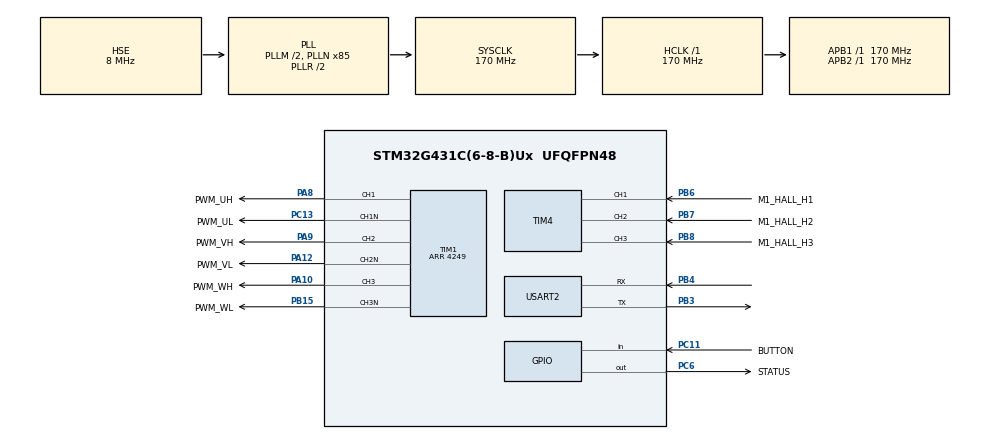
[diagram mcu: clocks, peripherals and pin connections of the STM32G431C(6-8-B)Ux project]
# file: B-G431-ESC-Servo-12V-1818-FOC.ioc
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Dma.Request0=USART2_RX
Dma.Request1=USART2_TX
Dma.USART2_RX.0.Direction=DMA_PERIPH_TO_MEMORY
Dma.USART2_RX.0.EventEnable=DISABLE
Dma.USART2_RX.0.Instance=DMA1_Channel1
Dma.USART2_RX.0.MemDataAlignment=DMA_MDATAALIGN_BYTE
Dma.USART2_RX.0.MemInc=DMA_MINC_ENABLE
Dma.USART2_RX.0.Mode=DMA_CIRCULAR
Dma.USART2_RX.0.PeriphDataAlignment=DMA_PDATAALIGN_BYTE
Dma.USART2_RX.0.PeriphInc=DMA_PINC_DISABLE
Dma.USART2_RX.0.Polarity=HAL_DMAMUX_REQ_GEN_RISING
Dma.USART2_RX.0.Priority=DMA_PRIORITY_LOW
Dma.USART2_RX.0.RequestNumber=1
Dma.USART2_RX.0.SignalID=NONE
Dma.USART2_RX.0.SyncEnable=DISABLE
Dma.USART2_RX.0.SyncPolarity=HAL_DMAMUX_SYNC_NO_EVENT
Dma.USART2_RX.0.SyncRequestNumber=1
Dma.USART2_RX.0.SyncSignalID=NONE
Dma.USART2_TX.1.Direction=DMA_MEMORY_TO_PERIPH
Dma.USART2_TX.1.EventEnable=DISABLE
Dma.USART2_TX.1.Instance=DMA1_Channel2
Dma.USART2_TX.1.MemDataAlignment=DMA_MDATAALIGN_BYTE
Dma.USART2_TX.1.MemInc=DMA_MINC_ENABLE
Dma.USART2_TX.1.Mode=DMA_NORMAL
Dma.USART2_TX.1.PeriphDataAlignment=DMA_PDATAALIGN_BYTE
Dma.USART2_TX.1.PeriphInc=DMA_PINC_DISABLE
Dma.USART2_TX.1.Polarity=HAL_DMAMUX_REQ_GEN_RISING
Dma.USART2_TX.1.Priority=DMA_PRIORITY_LOW
Dma.USART2_TX.1.RequestNumber=1
Dma.USART2_TX.1.SignalID=NONE
Dma.USART2_TX.1.SyncEnable=DISABLE
Dma.USART2_TX.1.SyncPolarity=HAL_DMAMUX_SYNC_NO_EVENT
Dma.USART2_TX.1.SyncRequestNumber=1
Dma.USART2_TX.1.SyncSignalID=NONE
Mcu.Family=STM32G4
Mcu.Name=STM32G431C(6-8-B)Ux
Mcu.Package=UFQFPN48
NVIC.DMA1_Channel1_IRQn=true\:0\:0\:false\:false\:true\:false\:true\:true
NVIC.DMA1_Channel2_IRQn=true\:0\:0\:false\:false\:true\:false\:true\:true
NVIC.PriorityGroup=NVIC_PRIORITYGROUP_4
NVIC.TIM1_UP_TIM16_IRQn=true\:0\:0\:false\:false\:true\:true\:false\:true
NVIC.TIM4_IRQn=true\:0\:0\:false\:false\:true\:true\:false\:true
NVIC.USART2_IRQn=true\:0\:0\:false\:false\:true\:true\:true\:true
PA10.GPIO_Label=PWM_WH
PA10.GPIO_PuPd=GPIO_PULLDOWN
PA10.Signal=S_TIM1_CH3
PA12.GPIO_Label=PWM_VL
PA12.GPIO_PuPd=GPIO_PULLDOWN
PA12.Mode=PWM Generation2 CH2 CH2N
PA12.Signal=TIM1_CH2N
PA13.Mode=Serial_Wire
PA13.Signal=SYS_JTMS-SWDIO
PA14.Mode=Serial_Wire
PA14.Signal=SYS_JTCK-SWCLK
PA8.GPIO_Label=PWM_UH
PA8.GPIO_PuPd=GPIO_PULLDOWN
PA8.Signal=S_TIM1_CH1
PA9.GPIO_Label=PWM_VH
PA9.GPIO_PuPd=GPIO_PULLDOWN
PA9.Signal=S_TIM1_CH2
PB15.GPIO_Label=PWM_WL
PB15.GPIO_PuPd=GPIO_PULLDOWN
PB15.Mode=PWM Generation3 CH3 CH3N
PB15.Signal=TIM1_CH3N
PB3.Mode=Asynchronous
PB3.Signal=USART2_TX
PB4.Mode=Asynchronous
PB4.Signal=USART2_RX
PB6.GPIO_Label=M1_HALL_H1
PB6.GPIO_PuPd=GPIO_PULLUP
PB6.GPIO_Speed=GPIO_SPEED_FREQ_HIGH
PB6.Signal=S_TIM4_CH1
PB7.GPIO_Label=M1_HALL_H2
PB7.GPIO_PuPd=GPIO_PULLUP
PB7.GPIO_Speed=GPIO_SPEED_FREQ_HIGH
PB7.Signal=S_TIM4_CH2
PB8-BOOT0.GPIO_Label=M1_HALL_H3
PB8-BOOT0.GPIO_PuPd=GPIO_PULLUP
PB8-BOOT0.GPIO_Speed=GPIO_SPEED_FREQ_HIGH
PB8-BOOT0.Signal=S_TIM4_CH3
PC11.GPIO_Label=BUTTON
PC11.Signal=GPIO_Input
PC13.GPIO_Label=PWM_UL
PC13.GPIO_PuPd=GPIO_PULLDOWN
PC13.Mode=PWM Generation1 CH1 CH1N
PC13.Signal=TIM1_CH1N
PC6.GPIO_Label=STATUS
PC6.Signal=GPIO_Output
PF0-OSC_IN.Mode=HSE-External-Oscillator
PF0-OSC_IN.Signal=RCC_OSC_IN
PF1-OSC_OUT.Mode=HSE-External-Oscillator
PF1-OSC_OUT.Signal=RCC_OSC_OUT
ProjectManager.HeapSize=0x200
ProjectManager.StackSize=0x400
ProjectManager.TargetToolchain=MDK-ARM V5.32
RCC.ADC12Freq_Value=170000000
RCC.AHBFreq_Value=170000000
RCC.APB1Freq_Value=170000000
RCC.APB1TimFreq_Value=170000000
RCC.APB2Freq_Value=170000000
RCC.APB2TimFreq_Value=170000000
RCC.CortexFreq_Value=170000000
RCC.EXTERNAL_CLOCK_VALUE=12288000
RCC.HCLKFreq_Value=170000000
RCC.HSE_VALUE=8000000
RCC.HSI48_VALUE=48000000
RCC.HSI_VALUE=16000000
RCC.LSE_VALUE=32768
RCC.PLLM=RCC_PLLM_DIV2
RCC.PLLN=85
RCC.PLLSourceVirtual=RCC_PLLSOURCE_HSE
RCC.SYSCLKFreq_VALUE=170000000
RCC.SYSCLKSource=RCC_SYSCLKSOURCE_PLLCLK
RCC.USBFreq_Value=170000000
RCC.VCOOutputFreq_Value=340000000
SH.S_TIM1_CH1.0=TIM1_CH1,PWM Generation1 CH1 CH1N
SH.S_TIM1_CH2.0=TIM1_CH2,PWM Generation2 CH2 CH2N
SH.S_TIM1_CH3.0=TIM1_CH3,PWM Generation3 CH3 CH3N
SH.S_TIM4_CH1.0=TIM4_CH1,Xored_Inputs_Hall_Sensor_Interface
SH.S_TIM4_CH2.0=TIM4_CH2,Xored_Inputs_Hall_Sensor_Interface
SH.S_TIM4_CH3.0=TIM4_CH3,Xored_Inputs_Hall_Sensor_Interface
TIM1.Channel-PWM\ Generation1\ CH1\ CH1N=TIM_CHANNEL_1
TIM1.Channel-PWM\ Generation2\ CH2\ CH2N=TIM_CHANNEL_2
TIM1.Channel-PWM\ Generation3\ CH3\ CH3N=TIM_CHANNEL_3
TIM1.CounterMode=TIM_COUNTERMODE_CENTERALIGNED1
TIM1.DeadTime=169
TIM1.OC1Preload_PWM=ENABLE
TIM1.OC2Preload_PWM=ENABLE
TIM1.OC3Preload_PWM=ENABLE
TIM1.OffStateIDLEMode=TIM_OSSI_ENABLE
TIM1.OffStateRunMode=TIM_OSSR_ENABLE
TIM1.PeriodNoDither=4249
TIM1.RepetitionCounter=1
TIM4.IC1Filter=2
USART2.VirtualMode-Asynchronous=VM_ASYNC
VP_CORDIC_VS_CORDIC.Mode=CORDIC_Activate
VP_SYS_VS_DBSignals.Mode=DisableDeadBatterySignals
board=custom

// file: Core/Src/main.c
/* USER CODE BEGIN Header */
/**
  ******************************************************************************
  * @file           : main.c
  * @brief          : Main program body
  ******************************************************************************
  * @attention
  *
  * Copyright (c) 2024 STMicroelectronics.
  * All rights reserved.
  *
  * This software is licensed under terms that can be found in the LICENSE file
  * in the root directory of this software component.
  * If no LICENSE file comes with this software, it is provided AS-IS.
  *
  ******************************************************************************
  */
/* USER CODE END Header */
#include "main.h"

CORDIC_HandleTypeDef hcordic;

TIM_HandleTypeDef htim1;
TIM_HandleTypeDef htim4;

UART_HandleTypeDef huart2;
DMA_HandleTypeDef hdma_usart2_rx;
DMA_HandleTypeDef hdma_usart2_tx;

void SystemClock_Config(void);
static void MX_GPIO_Init(void);
static void MX_DMA_Init(void);

int main(void)
{

  /* MCU Configuration--------------------------------------------------------*/

  /* Reset of all peripherals, Initializes the Flash interface and the Systick. */
  HAL_Init();

  /* Configure the system clock */
  SystemClock_Config();

  /* Initialize all configured peripherals */
  MX_GPIO_Init();
  MX_DMA_Init();
  MX_TIM1_Init();
  MX_TIM4_Init();
  MX_USART2_UART_Init();
  MX_CORDIC_Init();
  /* USER CODE BEGIN 2 */
	tsk_main();
  /* USER CODE END 2 */

  /* Infinite loop */
  /* USER CODE BEGIN WHILE */
  while (1)
  {
		osRtxIdleThread(NULL);
    /* USER CODE END WHILE */

  }
}

void SystemClock_Config(void)
{
  RCC_OscInitTypeDef RCC_OscInitStruct = {0};
  RCC_ClkInitTypeDef RCC_ClkInitStruct = {0};

  /** Configure the main internal regulator output voltage
  */
  HAL_PWREx_ControlVoltageScaling(PWR_REGULATOR_VOLTAGE_SCALE1_BOOST);

  /** Initializes the RCC Oscillators according to the specified parameters
  * in the RCC_OscInitTypeDef structure.
  */
  RCC_OscInitStruct.OscillatorType = RCC_OSCILLATORTYPE_HSE;
  RCC_OscInitStruct.HSEState = RCC_HSE_ON;
  RCC_OscInitStruct.PLL.PLLState = RCC_PLL_ON;
  RCC_OscInitStruct.PLL.PLLSource = RCC_PLLSOURCE_HSE;
  RCC_OscInitStruct.PLL.PLLM = RCC_PLLM_DIV2;
  RCC_OscInitStruct.PLL.PLLN = 85;
  RCC_OscInitStruct.PLL.PLLP = RCC_PLLP_DIV2;
  RCC_OscInitStruct.PLL.PLLQ = RCC_PLLQ_DIV2;
  RCC_OscInitStruct.PLL.PLLR = RCC_PLLR_DIV2;
  if (HAL_RCC_OscConfig(&RCC_OscInitStruct) != HAL_OK)
  {
    Error_Handler();
  }

  /** Initializes the CPU, AHB and APB buses clocks
  */
  RCC_ClkInitStruct.ClockType = RCC_CLOCKTYPE_HCLK|RCC_CLOCKTYPE_SYSCLK
                              |RCC_CLOCKTYPE_PCLK1|RCC_CLOCKTYPE_PCLK2;
  RCC_ClkInitStruct.SYSCLKSource = RCC_SYSCLKSOURCE_PLLCLK;
  RCC_ClkInitStruct.AHBCLKDivider = RCC_SYSCLK_DIV1;
  RCC_ClkInitStruct.APB1CLKDivider = RCC_HCLK_DIV1;
  RCC_ClkInitStruct.APB2CLKDivider = RCC_HCLK_DIV1;

  if (HAL_RCC_ClockConfig(&RCC_ClkInitStruct, FLASH_LATENCY_4) != HAL_OK)
  {
    Error_Handler();
  }
}

void MX_CORDIC_Init(void)
{

  hcordic.Instance = CORDIC;
  if (HAL_CORDIC_Init(&hcordic) != HAL_OK)
  {
    Error_Handler();
  }

}

void MX_TIM1_Init(void)
{

  TIM_MasterConfigTypeDef sMasterConfig = {0};
  TIM_OC_InitTypeDef sConfigOC = {0};
  TIM_BreakDeadTimeConfigTypeDef sBreakDeadTimeConfig = {0};

  htim1.Instance = TIM1;
  htim1.Init.Prescaler = 0;
  htim1.Init.CounterMode = TIM_COUNTERMODE_CENTERALIGNED1;
  htim1.Init.Period = 4249;
  htim1.Init.ClockDivision = TIM_CLOCKDIVISION_DIV1;
  htim1.Init.RepetitionCounter = 1;
  htim1.Init.AutoReloadPreload = TIM_AUTORELOAD_PRELOAD_DISABLE;
  if (HAL_TIM_PWM_Init(&htim1) != HAL_OK)
  {
    Error_Handler();
  }
  sMasterConfig.MasterOutputTrigger = TIM_TRGO_RESET;
  sMasterConfig.MasterOutputTrigger2 = TIM_TRGO2_RESET;
  sMasterConfig.MasterSlaveMode = TIM_MASTERSLAVEMODE_DISABLE;
  if (HAL_TIMEx_MasterConfigSynchronization(&htim1, &sMasterConfig) != HAL_OK)
  {
    Error_Handler();
  }
  sConfigOC.OCMode = TIM_OCMODE_PWM1;
  sConfigOC.Pulse = 0;
  sConfigOC.OCPolarity = TIM_OCPOLARITY_HIGH;
  sConfigOC.OCNPolarity = TIM_OCNPOLARITY_HIGH;
  sConfigOC.OCFastMode = TIM_OCFAST_DISABLE;
  sConfigOC.OCIdleState = TIM_OCIDLESTATE_RESET;
  sConfigOC.OCNIdleState = TIM_OCNIDLESTATE_RESET;
  if (HAL_TIM_PWM_ConfigChannel(&htim1, &sConfigOC, TIM_CHANNEL_1) != HAL_OK)
  {
    Error_Handler();
  }
  if (HAL_TIM_PWM_ConfigChannel(&htim1, &sConfigOC, TIM_CHANNEL_2) != HAL_OK)
  {
    Error_Handler();
  }
  if (HAL_TIM_PWM_ConfigChannel(&htim1, &sConfigOC, TIM_CHANNEL_3) != HAL_OK)
  {
    Error_Handler();
  }
  sBreakDeadTimeConfig.OffStateRunMode = TIM_OSSR_ENABLE;
  sBreakDeadTimeConfig.OffStateIDLEMode = TIM_OSSI_ENABLE;
  sBreakDeadTimeConfig.LockLevel = TIM_LOCKLEVEL_OFF;
  sBreakDeadTimeConfig.DeadTime = 169;
  sBreakDeadTimeConfig.BreakState = TIM_BREAK_DISABLE;
  sBreakDeadTimeConfig.BreakPolarity = TIM_BREAKPOLARITY_HIGH;
  sBreakDeadTimeConfig.BreakFilter = 0;
  sBreakDeadTimeConfig.BreakAFMode = TIM_BREAK_AFMODE_INPUT;
  sBreakDeadTimeConfig.Break2State = TIM_BREAK2_DISABLE;
  sBreakDeadTimeConfig.Break2Polarity = TIM_BREAK2POLARITY_HIGH;
  sBreakDeadTimeConfig.Break2Filter = 0;
  sBreakDeadTimeConfig.Break2AFMode = TIM_BREAK_AFMODE_INPUT;
  sBreakDeadTimeConfig.AutomaticOutput = TIM_AUTOMATICOUTPUT_DISABLE;
  if (HAL_TIMEx_ConfigBreakDeadTime(&htim1, &sBreakDeadTimeConfig) != HAL_OK)
  {
    Error_Handler();
  }
  HAL_TIM_MspPostInit(&htim1);

}

void MX_TIM4_Init(void)
{

  TIM_HallSensor_InitTypeDef sConfig = {0};
  TIM_MasterConfigTypeDef sMasterConfig = {0};

  htim4.Instance = TIM4;
  htim4.Init.Prescaler = 0;
  htim4.Init.CounterMode = TIM_COUNTERMODE_UP;
  htim4.Init.Period = 65535;
  htim4.Init.ClockDivision = TIM_CLOCKDIVISION_DIV1;
  htim4.Init.AutoReloadPreload = TIM_AUTORELOAD_PRELOAD_DISABLE;
  sConfig.IC1Polarity = TIM_ICPOLARITY_RISING;
  sConfig.IC1Prescaler = TIM_ICPSC_DIV1;
  sConfig.IC1Filter = 2;
  sConfig.Commutation_Delay = 0;
  if (HAL_TIMEx_HallSensor_Init(&htim4, &sConfig) != HAL_OK)
  {
    Error_Handler();
  }
  sMasterConfig.MasterOutputTrigger = TIM_TRGO_OC2REF;
  sMasterConfig.MasterSlaveMode = TIM_MASTERSLAVEMODE_DISABLE;
  if (HAL_TIMEx_MasterConfigSynchronization(&htim4, &sMasterConfig) != HAL_OK)
  {
    Error_Handler();
  }

}

void MX_USART2_UART_Init(void)
{

  huart2.Instance = USART2;
  huart2.Init.BaudRate = 115200;
  huart2.Init.WordLength = UART_WORDLENGTH_8B;
  huart2.Init.StopBits = UART_STOPBITS_1;
  huart2.Init.Parity = UART_PARITY_NONE;
  huart2.Init.Mode = UART_MODE_TX_RX;
  huart2.Init.HwFlowCtl = UART_HWCONTROL_NONE;
  huart2.Init.OverSampling = UART_OVERSAMPLING_16;
  huart2.Init.OneBitSampling = UART_ONE_BIT_SAMPLE_DISABLE;
  huart2.Init.ClockPrescaler = UART_PRESCALER_DIV1;
  huart2.AdvancedInit.AdvFeatureInit = UART_ADVFEATURE_NO_INIT;
  if (HAL_UART_Init(&huart2) != HAL_OK)
  {
    Error_Handler();
  }
  if (HAL_UARTEx_SetTxFifoThreshold(&huart2, UART_TXFIFO_THRESHOLD_1_8) != HAL_OK)
  {
    Error_Handler();
  }
  if (HAL_UARTEx_SetRxFifoThreshold(&huart2, UART_RXFIFO_THRESHOLD_1_8) != HAL_OK)
  {
    Error_Handler();
  }
  if (HAL_UARTEx_DisableFifoMode(&huart2) != HAL_OK)
  {
    Error_Handler();
  }

}

static void MX_DMA_Init(void)
{

  /* DMA controller clock enable */
  __HAL_RCC_DMAMUX1_CLK_ENABLE();
  __HAL_RCC_DMA1_CLK_ENABLE();

  /* DMA interrupt init */
  /* DMA1_Channel1_IRQn interrupt configuration */
  HAL_NVIC_SetPriority(DMA1_Channel1_IRQn, 0, 0);
  HAL_NVIC_EnableIRQ(DMA1_Channel1_IRQn);
  /* DMA1_Channel2_IRQn interrupt configuration */
  HAL_NVIC_SetPriority(DMA1_Channel2_IRQn, 0, 0);
  HAL_NVIC_EnableIRQ(DMA1_Channel2_IRQn);

}

static void MX_GPIO_Init(void)
{
  GPIO_InitTypeDef GPIO_InitStruct = {0};

  /* GPIO Ports Clock Enable */
  __HAL_RCC_GPIOC_CLK_ENABLE();
  __HAL_RCC_GPIOF_CLK_ENABLE();
  __HAL_RCC_GPIOG_CLK_ENABLE();
  __HAL_RCC_GPIOA_CLK_ENABLE();
  __HAL_RCC_GPIOB_CLK_ENABLE();

  /*Configure GPIO pin Output Level */
  HAL_GPIO_WritePin(STATUS_GPIO_Port, STATUS_Pin, GPIO_PIN_RESET);

  /*Configure GPIO pins : PC14 PC15 PC4 PC10 */
  GPIO_InitStruct.Pin = GPIO_PIN_14|GPIO_PIN_15|GPIO_PIN_4|GPIO_PIN_10;
  GPIO_InitStruct.Mode = GPIO_MODE_ANALOG;
  GPIO_InitStruct.Pull = GPIO_NOPULL;
  HAL_GPIO_Init(GPIOC, &GPIO_InitStruct);

  /*Configure GPIO pin : PG10 */
  GPIO_InitStruct.Pin = GPIO_PIN_10;
  GPIO_InitStruct.Mode = GPIO_MODE_ANALOG;
  GPIO_InitStruct.Pull = GPIO_NOPULL;
  HAL_GPIO_Init(GPIOG, &GPIO_InitStruct);

  /*Configure GPIO pins : PA0 PA1 PA2 PA3
                           PA4 PA5 PA6 PA7
                           PA11 PA15 */
  GPIO_InitStruct.Pin = GPIO_PIN_0|GPIO_PIN_1|GPIO_PIN_2|GPIO_PIN_3
                          |GPIO_PIN_4|GPIO_PIN_5|GPIO_PIN_6|GPIO_PIN_7
                          |GPIO_PIN_11|GPIO_PIN_15;
  GPIO_InitStruct.Mode = GPIO_MODE_ANALOG;
  GPIO_InitStruct.Pull = GPIO_NOPULL;
  HAL_GPIO_Init(GPIOA, &GPIO_InitStruct);

  /*Configure GPIO pins : PB0 PB1 PB2 PB10
                           PB11 PB12 PB13 PB14
                           PB5 PB9 */
  GPIO_InitStruct.Pin = GPIO_PIN_0|GPIO_PIN_1|GPIO_PIN_2|GPIO_PIN_10
                          |GPIO_PIN_11|GPIO_PIN_12|GPIO_PIN_13|GPIO_PIN_14
                          |GPIO_PIN_5|GPIO_PIN_9;
  GPIO_InitStruct.Mode = GPIO_MODE_ANALOG;
  GPIO_InitStruct.Pull = GPIO_NOPULL;
  HAL_GPIO_Init(GPIOB, &GPIO_InitStruct);

  /*Configure GPIO pin : STATUS_Pin */
  GPIO_InitStruct.Pin = STATUS_Pin;
  GPIO_InitStruct.Mode = GPIO_MODE_OUTPUT_PP;
  GPIO_InitStruct.Pull = GPIO_NOPULL;
  GPIO_InitStruct.Speed = GPIO_SPEED_FREQ_LOW;
  HAL_GPIO_Init(STATUS_GPIO_Port, &GPIO_InitStruct);

  /*Configure GPIO pin : BUTTON_Pin */
  GPIO_InitStruct.Pin = BUTTON_Pin;
  GPIO_InitStruct.Mode = GPIO_MODE_INPUT;
  GPIO_InitStruct.Pull = GPIO_NOPULL;
  HAL_GPIO_Init(BUTTON_GPIO_Port, &GPIO_InitStruct);

}

void Error_Handler(void)
{
  __disable_irq();
  while (1)
  {
  }
}
